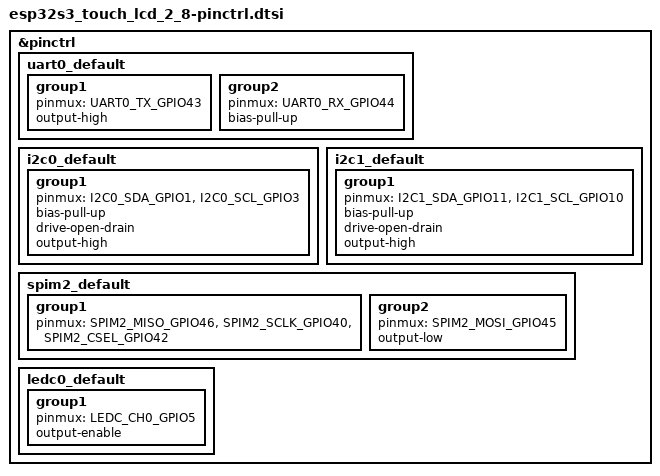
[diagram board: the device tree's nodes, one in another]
/*
 * Copyright (c) 2025 Harry Jiang
 * SPDX-License-Identifier: Apache-2.0
 */

#include <dt-bindings/pinctrl/esp32s3-pinctrl.h>
#include <zephyr/dt-bindings/pinctrl/esp-pinctrl-common.h>
#include <zephyr/dt-bindings/pinctrl/esp32s3-gpio-sigmap.h>

&pinctrl {
	uart0_default: uart0_default {
		group1 {
			pinmux = <UART0_TX_GPIO43>;
			output-high;
		};
		group2 {
			pinmux = <UART0_RX_GPIO44>;
			bias-pull-up;
		};
	};

	i2c0_default: i2c0_default {
		group1 {
			pinmux = <I2C0_SDA_GPIO1>,
			 <I2C0_SCL_GPIO3>;
			bias-pull-up;
			drive-open-drain;
			output-high;
		};
	};

	i2c1_default: i2c1_default {
		group1 {
			pinmux = <I2C1_SDA_GPIO11>,
			 <I2C1_SCL_GPIO10>;
			bias-pull-up;
			drive-open-drain;
			output-high;
		};
	};

	spim2_default: spim2_default {
		group1 {
			pinmux = <SPIM2_MISO_GPIO46>,
			<SPIM2_SCLK_GPIO40>,
			<SPIM2_CSEL_GPIO42>;
		};
		group2 {
			pinmux = <SPIM2_MOSI_GPIO45>;
			output-low;
		};
	};

	ledc0_default: ledc0_default {
		group1 {
			pinmux = <LEDC_CH0_GPIO5>;
			output-enable;
		};
	};
}; 
